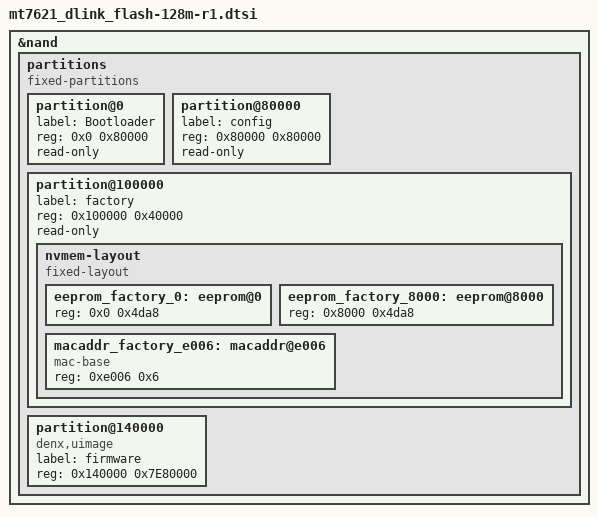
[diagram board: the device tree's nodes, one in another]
// SPDX-License-Identifier: GPL-2.0-or-later OR MIT

&nand {
	status = "okay";

	partitions {
		compatible = "fixed-partitions";
		#address-cells = <1>;
		#size-cells = <1>;

		partition@0 {
			label = "Bootloader";
			reg = <0x0 0x80000>;
			read-only;
		};

		partition@80000 {
			label = "config";
			reg = <0x80000 0x80000>;
			read-only;
		};

		partition@100000 {
			label = "factory";
			reg = <0x100000 0x40000>;
			read-only;

			nvmem-layout {
				compatible = "fixed-layout";
				#address-cells = <1>;
				#size-cells = <1>;

				eeprom_factory_0: eeprom@0 {
					reg = <0x0 0x4da8>;
				};

				eeprom_factory_8000: eeprom@8000 {
					reg = <0x8000 0x4da8>;
				};

				macaddr_factory_e006: macaddr@e006 {
					compatible = "mac-base";
					reg = <0xe006 0x6>;
					#nvmem-cell-cells = <1>;
				};
			};
		};

			partition@140000 {
			label = "firmware";
			compatible = "denx,uimage";
			reg = <0x140000 0x7E80000>;
		};
	};
};
